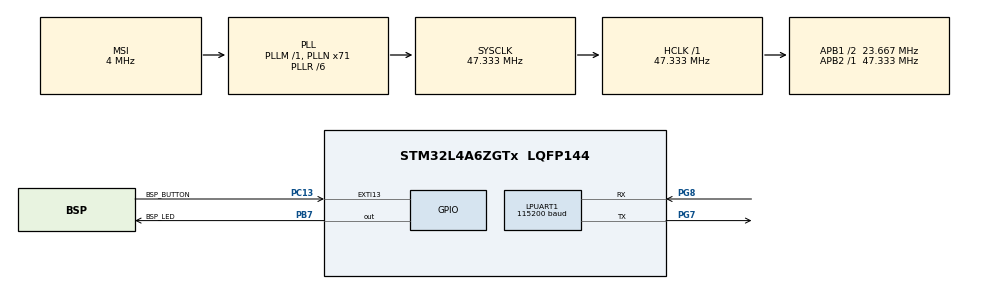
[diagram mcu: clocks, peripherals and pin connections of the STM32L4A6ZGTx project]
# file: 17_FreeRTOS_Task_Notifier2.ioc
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FREERTOS.Tasks01=ButtonTask,24,128,StartButtonTask,Default,NULL,Dynamic,NULL,NULL
FREERTOS.configUSE_NEWLIB_REENTRANT=1
LPUART1.BaudRate=115200
LPUART1.WordLength=UART_WORDLENGTH_8B
Mcu.Family=STM32L4
Mcu.Name=STM32L4A6ZGTx
Mcu.Package=LQFP144
NVIC.EXTI15_10_IRQn=true\:5\:0\:false\:false\:true\:true\:true\:true\:true
NVIC.PriorityGroup=NVIC_PRIORITYGROUP_4
NVIC.TIM6_DAC_IRQn=true\:15\:0\:false\:false\:true\:false\:false\:true\:true
NVIC.TimeBase=TIM6_DAC_IRQn
NVIC.TimeBaseIP=TIM6
PA13\ (JTMS/SWDIO).Mode=Trace_Asynchronous_SW
PA13\ (JTMS/SWDIO).Signal=SYS_JTMS-SWDIO
PA14\ (JTCK/SWCLK).Mode=Trace_Asynchronous_SW
PA14\ (JTCK/SWCLK).Signal=SYS_JTCK-SWCLK
PB3\ (JTDO/TRACESWO).Mode=Trace_Asynchronous_SW
PB3\ (JTDO/TRACESWO).Signal=SYS_JTDO-SWO
PB7.GPIO_Label=BSP_LED
PB7.Signal=GPIO_Output
PC13.GPIO_Label=BSP_BUTTON
PC13.Signal=GPXTI13
PG7.Mode=Asynchronous
PG7.Signal=LPUART1_TX
PG8.Mode=Asynchronous
PG8.Signal=LPUART1_RX
ProjectManager.HeapSize=0x200
ProjectManager.StackSize=0x400
ProjectManager.TargetToolchain=STM32CubeIDE
RCC.ADCFreq_Value=48000000
RCC.AHBFreq_Value=47333333.333333336
RCC.APB1CLKDivider=RCC_HCLK_DIV2
RCC.APB1Freq_Value=23666666.666666668
RCC.APB1TimFreq_Value=47333333.333333336
RCC.APB2Freq_Value=47333333.333333336
RCC.APB2TimFreq_Value=47333333.333333336
RCC.CortexFreq_Value=47333333.333333336
RCC.FLatency=FLASH_LATENCY_2
RCC.HCLKFreq_Value=47333333.333333336
RCC.HSE_VALUE=8000000
RCC.HSI48_VALUE=48000000
RCC.HSI_VALUE=16000000
RCC.LSE_VALUE=32768
RCC.MSI_VALUE=4000000
RCC.PLLN=71
RCC.PLLR=RCC_PLLR_DIV6
RCC.PLLSAI1N=24
RCC.SYSCLKFreq_VALUE=47333333.333333336
RCC.SYSCLKSource=RCC_SYSCLKSOURCE_PLLCLK
RCC.USBFreq_Value=48000000
RCC.VCOOutputFreq_Value=284000000
VP_FREERTOS_VS_CMSIS_V2.Mode=CMSIS_V2
VP_SYS_VS_tim6.Mode=TIM6
board=NUCLEO-L4A6ZG

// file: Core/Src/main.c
/* USER CODE BEGIN Header */
/**
  ******************************************************************************
  * @file           : main.c
  * @brief          : Main program body
  ******************************************************************************
  * @attention
  *
  * Copyright (c) 2024 STMicroelectronics.
  * All rights reserved.
  *
  * This software is licensed under terms that can be found in the LICENSE file
  * in the root directory of this software component.
  * If no LICENSE file comes with this software, it is provided AS-IS.
  *
  ******************************************************************************
  */
/* USER CODE END Header */
#include "main.h"
#include "cmsis_os.h"

/* USER CODE BEGIN Includes */
#include <stdio.h>
/* USER CODE END Includes */

UART_HandleTypeDef hlpuart1;

/* Definitions for ButtonTask */
osThreadId_t ButtonTaskHandle;
const osThreadAttr_t ButtonTask_attributes = {
  .name = "ButtonTask",
  .stack_size = 128 * 4,
  .priority = (osPriority_t) osPriorityNormal,
};

void SystemClock_Config(void);
static void MX_GPIO_Init(void);
static void MX_LPUART1_UART_Init(void);
void StartButtonTask(void *argument);

int main(void)
{

  /* MCU Configuration--------------------------------------------------------*/

  /* Reset of all peripherals, Initializes the Flash interface and the Systick. */
  HAL_Init();

  /* Configure the system clock */
  SystemClock_Config();

  /* Initialize all configured peripherals */
  MX_GPIO_Init();
  MX_LPUART1_UART_Init();

  /* Init scheduler */
  osKernelInitialize();

  /* Create the thread(s) */
  /* creation of ButtonTask */
  ButtonTaskHandle = osThreadNew(StartButtonTask, NULL, &ButtonTask_attributes);

  /* Start scheduler */
  osKernelStart();

  /* We should never get here as control is now taken by the scheduler */

  /* Infinite loop */
  while (1)
  {

  }
}

void SystemClock_Config(void)
{
  RCC_OscInitTypeDef RCC_OscInitStruct = {0};
  RCC_ClkInitTypeDef RCC_ClkInitStruct = {0};

  /** Configure the main internal regulator output voltage
  */
  if (HAL_PWREx_ControlVoltageScaling(PWR_REGULATOR_VOLTAGE_SCALE1) != HAL_OK)
  {
    Error_Handler();
  }

  /** Initializes the RCC Oscillators according to the specified parameters
  * in the RCC_OscInitTypeDef structure.
  */
  RCC_OscInitStruct.OscillatorType = RCC_OSCILLATORTYPE_MSI;
  RCC_OscInitStruct.MSIState = RCC_MSI_ON;
  RCC_OscInitStruct.MSICalibrationValue = 0;
  RCC_OscInitStruct.MSIClockRange = RCC_MSIRANGE_6;
  RCC_OscInitStruct.PLL.PLLState = RCC_PLL_ON;
  RCC_OscInitStruct.PLL.PLLSource = RCC_PLLSOURCE_MSI;
  RCC_OscInitStruct.PLL.PLLM = 1;
  RCC_OscInitStruct.PLL.PLLN = 71;
  RCC_OscInitStruct.PLL.PLLP = RCC_PLLP_DIV2;
  RCC_OscInitStruct.PLL.PLLQ = RCC_PLLQ_DIV2;
  RCC_OscInitStruct.PLL.PLLR = RCC_PLLR_DIV6;
  if (HAL_RCC_OscConfig(&RCC_OscInitStruct) != HAL_OK)
  {
    Error_Handler();
  }

  /** Initializes the CPU, AHB and APB buses clocks
  */
  RCC_ClkInitStruct.ClockType = RCC_CLOCKTYPE_HCLK|RCC_CLOCKTYPE_SYSCLK
                              |RCC_CLOCKTYPE_PCLK1|RCC_CLOCKTYPE_PCLK2;
  RCC_ClkInitStruct.SYSCLKSource = RCC_SYSCLKSOURCE_PLLCLK;
  RCC_ClkInitStruct.AHBCLKDivider = RCC_SYSCLK_DIV1;
  RCC_ClkInitStruct.APB1CLKDivider = RCC_HCLK_DIV2;
  RCC_ClkInitStruct.APB2CLKDivider = RCC_HCLK_DIV1;

  if (HAL_RCC_ClockConfig(&RCC_ClkInitStruct, FLASH_LATENCY_2) != HAL_OK)
  {
    Error_Handler();
  }
}

static void MX_LPUART1_UART_Init(void)
{

  hlpuart1.Instance = LPUART1;
  hlpuart1.Init.BaudRate = 115200;
  hlpuart1.Init.WordLength = UART_WORDLENGTH_8B;
  hlpuart1.Init.StopBits = UART_STOPBITS_1;
  hlpuart1.Init.Parity = UART_PARITY_NONE;
  hlpuart1.Init.Mode = UART_MODE_TX_RX;
  hlpuart1.Init.HwFlowCtl = UART_HWCONTROL_NONE;
  hlpuart1.Init.OneBitSampling = UART_ONE_BIT_SAMPLE_DISABLE;
  hlpuart1.AdvancedInit.AdvFeatureInit = UART_ADVFEATURE_NO_INIT;
  if (HAL_UART_Init(&hlpuart1) != HAL_OK)
  {
    Error_Handler();
  }

}

static void MX_GPIO_Init(void)
{
  GPIO_InitTypeDef GPIO_InitStruct = {0};

  /* GPIO Ports Clock Enable */
  __HAL_RCC_GPIOC_CLK_ENABLE();
  __HAL_RCC_GPIOG_CLK_ENABLE();
  HAL_PWREx_EnableVddIO2();
  __HAL_RCC_GPIOA_CLK_ENABLE();
  __HAL_RCC_GPIOB_CLK_ENABLE();

  /*Configure GPIO pin Output Level */
  HAL_GPIO_WritePin(BSP_LED_GPIO_Port, BSP_LED_Pin, GPIO_PIN_RESET);

  /*Configure GPIO pin : BSP_BUTTON_Pin */
  GPIO_InitStruct.Pin = BSP_BUTTON_Pin;
  GPIO_InitStruct.Mode = GPIO_MODE_IT_RISING;
  GPIO_InitStruct.Pull = GPIO_NOPULL;
  HAL_GPIO_Init(BSP_BUTTON_GPIO_Port, &GPIO_InitStruct);

  /*Configure GPIO pin : BSP_LED_Pin */
  GPIO_InitStruct.Pin = BSP_LED_Pin;
  GPIO_InitStruct.Mode = GPIO_MODE_OUTPUT_PP;
  GPIO_InitStruct.Pull = GPIO_NOPULL;
  GPIO_InitStruct.Speed = GPIO_SPEED_FREQ_LOW;
  HAL_GPIO_Init(BSP_LED_GPIO_Port, &GPIO_InitStruct);

  /* EXTI interrupt init*/
  HAL_NVIC_SetPriority(EXTI15_10_IRQn, 5, 0);
  HAL_NVIC_EnableIRQ(EXTI15_10_IRQn);

}

/* USER CODE BEGIN 4 */
void HAL_GPIO_EXTI_Callback(uint16_t GPIO_Pin)
{
	if(GPIO_Pin == GPIO_PIN_13)
	{
		BaseType_t xHigherPriorityTaskWoken = pdTRUE;

		/* Notify the task from ISR */
		vTaskNotifyGiveFromISR(ButtonTaskHandle, &xHigherPriorityTaskWoken);

		/* check if higher priority task woken, and request a context switch if necessary */
		portYIELD_FROM_ISR(xHigherPriorityTaskWoken);
	}
}
/* USER CODE END 4 */

void StartButtonTask(void *argument)
{/* USER CODE BEGIN 5 */
	  uint32_t notificationValue;

	  /* Infinite loop */
	  for(;;)
	  {
	    /* wait for a notification from the interrupt handler */
	    if(xTaskNotifyWait(3, 0, &notificationValue, portMAX_DELAY) == pdTRUE)
	    {
	      if(notificationValue >= 1) // Changed condition to check any non-zero notification
	      {
	    	HAL_GPIO_WritePin(BSP_LED_GPIO_Port, BSP_LED_Pin, GPIO_PIN_SET);
	        printf("Button pressed, LED on for 2 seconds\r\n"); // Debug message
	        osDelay(2000);
	        HAL_GPIO_WritePin(BSP_LED_GPIO_Port, BSP_LED_Pin, GPIO_PIN_RESET);
	      }
	    }
	    osDelay(100);
	  }
	  /* USER CODE END 5 */}

void HAL_TIM_PeriodElapsedCallback(TIM_HandleTypeDef *htim)
{
  if (htim->Instance == TIM6) {
    HAL_IncTick();
  }
}

void Error_Handler(void)
{
  __disable_irq();
  while (1)
  {
  }
}
